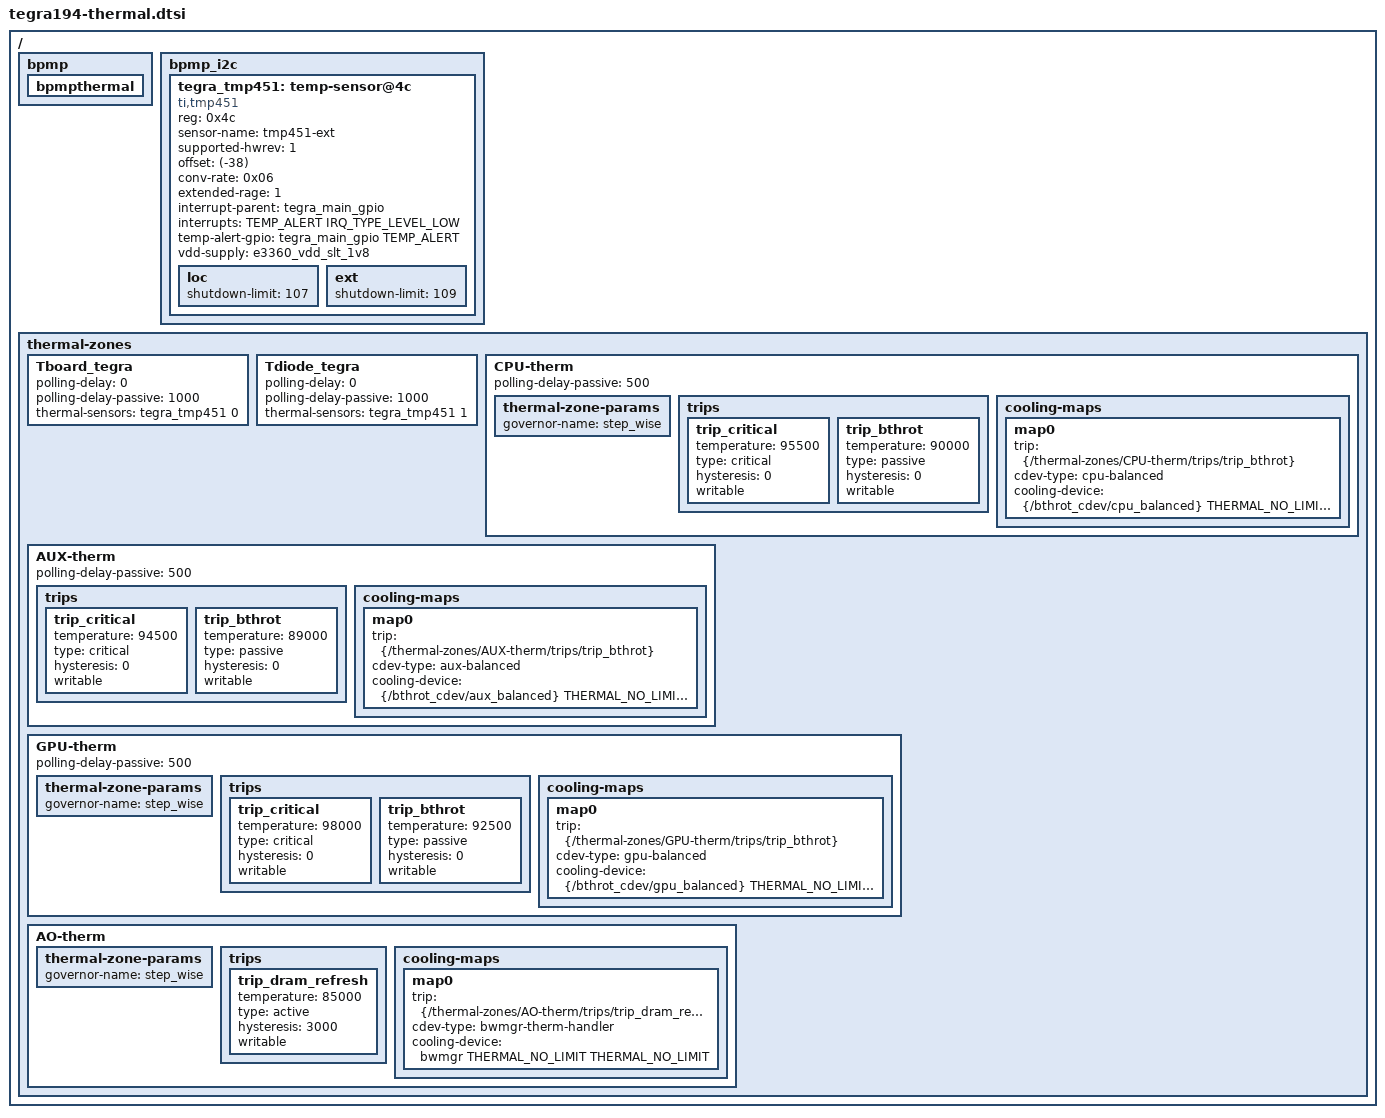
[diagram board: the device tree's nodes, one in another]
/*
 * Copyright (c) 2017, NVIDIA CORPORATION. All rights reserved.
 *
 * This program is free software; you can redistribute it and/or modify it
 * under the terms and conditions of the GNU General Public License,
 * version 2, as published by the Free Software Foundation.
 *
 * This program is distributed in the hope it will be useful, but WITHOUT
 * ANY WARRANTY; without even the implied warranty of MERCHANTABILITY or
 * FITNESS FOR A PARTICULAR PURPOSE.  See the GNU General Public License for
 * more details.
 *
 * You should have received a copy of the GNU General Public License
 * along with this program.  If not, see <http://www.gnu.org/licenses/>.
 */

#include <dt-bindings/interrupt-controller/arm-gic.h>
#include <dt-bindings/gpio/tegra194-gpio.h>
#include <dt-bindings/thermal/thermal.h>
#include "tegra194-balanced-throttle.dtsi"
#include "tegra194-pwm-fan.dtsi"
#include "tegra194-thermal-fan-est.dtsi"
/* THERMAL gpio definitions */
#define TEMP_ALERT TEGRA194_MAIN_GPIO(H, 2)

/ {
	bpmp {
		bpmpthermal {
			status = "okay";
		};
	};

	bpmp_i2c {
		tegra_tmp451: temp-sensor@4c {
			status = "okay";
			#thermal-sensor-cells = <1>;
			compatible = "ti,tmp451";
			reg = <0x4c>;
			sensor-name = "tmp451-ext";
			supported-hwrev = <1>;
			offset = <(-38)>;
			conv-rate = <0x06>;
			extended-rage = <1>;

			interrupt-parent = <&tegra_main_gpio>;
			interrupts = <TEMP_ALERT IRQ_TYPE_LEVEL_LOW>;
			temp-alert-gpio = <&tegra_main_gpio TEMP_ALERT 0>;

			vdd-supply = <&e3360_vdd_slt_1v8>;

			/* vdd-supply configured in power tree */

			loc {
				/* set to maximum for not having local  shutdown */
				shutdown-limit = <107>;
			};
			ext {
				shutdown-limit = <109>;
			};
		};
	};

	thermal-zones {
		status = "okay";

		Tboard_tegra: Tboard_tegra {
			status = "okay";
			polling-delay = <0>;
			polling-delay-passive = <1000>;
			thermal-sensors = <&tegra_tmp451 0>;
		};

		Tdiode_tegra: Tdiode_tegra {
			status = "okay";
			polling-delay = <0>;
			polling-delay-passive = <1000>;
			thermal-sensors = <&tegra_tmp451 1>;
		};
		CPU-therm {
			status = "okay";
			polling-delay-passive = <500>;

			thermal-zone-params {
				governor-name = "step_wise";
			};

			trips {
				trip_critical {
					temperature = <95500>;
					type = "critical";
					hysteresis = <0>;
					writable;
				};
				trip_bthrot {
					temperature = <90000>;
					type = "passive";
					hysteresis = <0>;
					writable;
				};
			};
			cooling-maps {
				map0 {
					trip = <&{/thermal-zones/CPU-therm/trips/trip_bthrot}>;
					cdev-type = "cpu-balanced";
					cooling-device = <&{/bthrot_cdev/cpu_balanced} THERMAL_NO_LIMIT THERMAL_NO_LIMIT>;
				};
			};
		};

		AUX-therm {
			status = "okay";
			polling-delay-passive = <500>;
			trips {
				trip_critical {
					temperature = <94500>;
					type = "critical";
					hysteresis = <0>;
					writable;
				};

				trip_bthrot {
					temperature = <89000>;
					type = "passive";
					hysteresis = <0>;
					writable;
				};
			};
			cooling-maps {
				map0 {
					trip = <&{/thermal-zones/AUX-therm/trips/trip_bthrot}>;
					cdev-type = "aux-balanced";
					cooling-device = <&{/bthrot_cdev/aux_balanced} THERMAL_NO_LIMIT THERMAL_NO_LIMIT>;
				};
			};
		};

		GPU-therm {
			status = "okay";
			polling-delay-passive = <500>;

			thermal-zone-params {
				governor-name = "step_wise";
			};

			trips {
				trip_critical {
					temperature = <98000>;
					type = "critical";
					hysteresis = <0>;
					writable;
				};
				trip_bthrot {
					temperature = <92500>;
					type = "passive";
					hysteresis = <0>;
					writable;
				};
			};
			cooling-maps {
				map0 {
					trip = <&{/thermal-zones/GPU-therm/trips/trip_bthrot}>;
					cdev-type = "gpu-balanced";
					cooling-device = <&{/bthrot_cdev/gpu_balanced} THERMAL_NO_LIMIT THERMAL_NO_LIMIT>;
				};
			};

		};

		AO-therm {
			status = "okay";

			thermal-zone-params {
				governor-name = "step_wise";
			};

			trips {
				trip_dram_refresh {
					temperature = <85000>;
					type = "active";
					hysteresis = <3000>;
					writable;
				};
			};
			cooling-maps {
				map0 {
					trip = <&{/thermal-zones/AO-therm/trips/trip_dram_refresh}>;
					cdev-type = "bwmgr-therm-handler";
					cooling-device = <&bwmgr THERMAL_NO_LIMIT THERMAL_NO_LIMIT>;
				};
			};
		};

	};
};
